# BAT32G135 register map
Vendor: CMS; Series: BAT32G135; File version: 1.2
CPU: CM0+ r0p1, little endian, no MPU, no FPU, VTOR, 2 interrupt priority bits
Registers are 8-bit, read-write, reset 0x0 unless marked. A register's access mark holds for its fields unless they carry their own. Offsets are from the block's base; [hi:lo] are bit positions; lines under a group give offsets from that group; {n}, {i} and the like mark numbered series.

## IICA — Serial Interface I2C with multimaster and wakeup supported
Base 0x40041A30
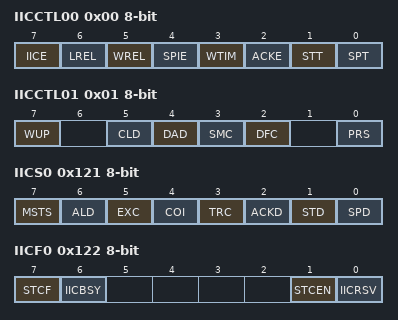
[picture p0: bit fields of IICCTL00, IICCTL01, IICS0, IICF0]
0x00 IICCTL00 — IICA control register 0
  [7] IICE — I2C operation enable
  [6] LREL — Exit from communications
  [5] WREL — Wait cancellation
  [4] SPIE — Enable generation of interrupt request when stop condition is detected
  [3] WTIM — Control of wait and interrupt request generation
  [2] ACKE — Acknowledgment control
  [1] STT — Start condition trigger
  [0] SPT — Stop condition trigger
0x01 IICCTL01 — IICA control register 0
  [7] WUP — Control of address match wakeup
  [5] CLD ro — Detection of SCLAn pin level (valid only when IICEn = 1)
  [4] DAD ro — Detection of SDAAn pin level (valid only when IICEn = 1)
  [3] SMC — Operation mode switching
  [2] DFC — Digital filter operation control
  [0] PRS — Operation clock (fMCK) contro
0x02 IICWL0 reset 0xFF — IICA low-level width setting register 0
0x03 IICWH0 reset 0xFF — IICA high-level width setting register 0
0x04 SVA0 (reset mask 0xFE) — Slave address register 0
0x120 IICA0 — IICA shift register 0
0x121 IICS0 ro — IICA status register 0
  [7] MSTS — Master status check flag
  [6] ALD — Detection of arbitration loss
  [5] EXC — Detection of extension code reception
  [4] COI — Detection of matching addresses
  [3] TRC — Detection of transmit/receive status
  [2] ACKD — Detection of acknowledge (ACK)
  [1] STD — Detection of start condition
  [0] SPD — Detection of stop condition
0x122 IICF0 — IICA flag register 0
  [7] STCF ro — STT clear flag
  [6] IICBSY ro — I2C bus status flag
  [1] STCEN — Initial start enable trigger
  [0] IICRSV — Communication reservation function disable bit

## IRDA — IrDA communication module based on Infrared Data Association stardard 1.0
Base 0x400440A0
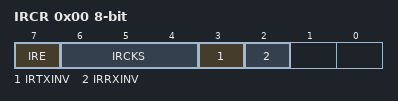
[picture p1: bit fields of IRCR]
0x00 IRCR — IrDA control register
  [7] IRE — IrRxD enable
  [6:4] IRCKS — IrRxD clock selection
  [3] IRTXINV — IrRxD data polarity switching
  [2] IRRXINV — IrRxD data polarity switching

## DMA — Enhanced DMA Controller
Base 0x40005000
{0x0+i} DMAEN{i} (i=0..2) — DMA activation enable register {i}
0x08 DMABAR 32-bit — DMA base address register
0x0C IFPRCR 32-bit — DMA Trigger Protect register
{0x10+i} DMAIF{i} (i=0..2) — DMA Trigger enable register {i}

## DMAVEC — DMA Vector and Control Data Area
Base 0x20000000
{0x0+i} VEC[{i}] (i=0..31) — DMA vector area
{0x20+0x10*i} CTRL[{i}] (i=0..23) group — DMA control data area
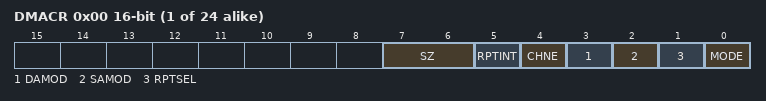
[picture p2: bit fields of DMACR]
  0x00 DMACR 16-bit — DMA Control register
    [7:6] SZ — Transfer Data size selection
      0=BYTE (8 bits); 1=HALF (16 bits); 2=WORD (32 bits)
    [5] RPTINT — Enabling/disabling repeat mode interrupts
      0=disable (Interrupt generation disabled); 1=enable (Interrupt generation enabled)
    [4] CHNE — Enabling/disabling chain transfers
      0=disable (Chain transfers disabled); 1=enable (Chain transfers enabled)
    [3] DAMOD — Destination address control
      0=Fixed; 1=Incremented
    [2] SAMOD — Source address control
      0=Fixed; 1=Incremented
    [1] RPTSEL — Repeat area selection
      0=destination (Transfer destination is the repeat area); 1=source (Transfer source is the repeat area)
    [0] MODE — Transfer mode selection
      0=Normal mode; 1=Repeat mode
  0x02 DMBLS 16-bit — DMA Block Size register
  0x04 DMACT 16-bit — DMA Transfer Count register
  0x06 DMRLD 16-bit — DMA Transfer Count Reload register
  0x08 DMSAR 32-bit — DMA Source Address register
  0x0C DMDAR 32-bit — DMA Destination Address register

## ELC — Event Link Controller
Base 0x40043400
{0x0+i} ELSELR{i:02} (reset mask 0xF) (i=0..14) — Event output destination select register {i:02}
